# PIC32MX564F128H register map
Vendor: Microchip
Registers are 32-bit, read-write, reset 0x0 unless marked. A register's access mark holds for its fields unless they carry their own. Addresses are absolute, and some are shared; only a register's first bit layout is shown; [hi:lo] are bit positions; {n}, {i} and the like mark numbered series.

## UART2
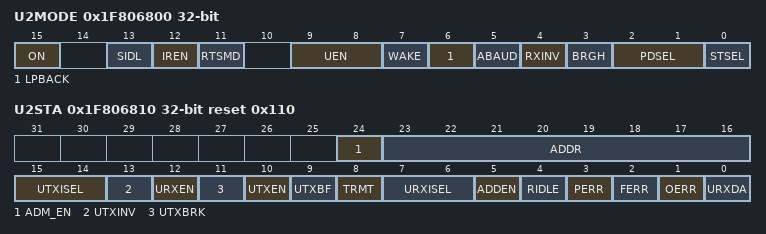
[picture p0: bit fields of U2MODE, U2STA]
0x1F806800 U2MODE
  [15] ON, [13] SIDL, [12] IREN, [11] RTSMD, [9:8] UEN, [7] WAKE, [6] LPBACK, [5] ABAUD, [4] RXINV, [3] BRGH, [2:1] PDSEL, [0] STSEL
0x1F806810 U2STA reset 0x110
  [24] ADM_EN
  [23:16] ADDR
  [15:14] UTXISEL
  [13] UTXINV
  [12] URXEN
  [11] UTXBRK
  [10] UTXEN
  [9] UTXBF ro
  [8] TRMT ro
  [7:6] URXISEL
  [5] ADDEN
  [4] RIDLE ro
  [3] PERR ro
  [2] FERR ro
  [1] OERR — (can only be cleared)
  [0] URXDA ro
0x1F806820 U2TXREG reset not defined — (power-on value -----------------------xxxxxxxxx)
  [8:0] U2TXREG
0x1F806830 U2RXREG ro
  [8:0] U2RXREG
0x1F806840 U2BRG
  [15:0] BRG

## UART5
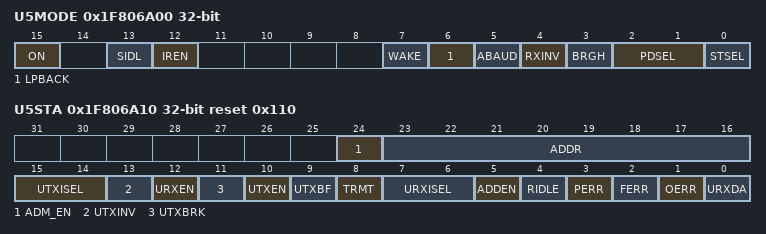
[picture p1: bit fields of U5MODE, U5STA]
0x1F806A00 U5MODE
  [15] ON, [13] SIDL, [12] IREN, [7] WAKE, [6] LPBACK, [5] ABAUD, [4] RXINV, [3] BRGH, [2:1] PDSEL, [0] STSEL
0x1F806A10 U5STA reset 0x110
  [24] ADM_EN
  [23:16] ADDR
  [15:14] UTXISEL
  [13] UTXINV
  [12] URXEN
  [11] UTXBRK
  [10] UTXEN
  [9] UTXBF ro
  [8] TRMT ro
  [7:6] URXISEL
  [5] ADDEN
  [4] RIDLE ro
  [3] PERR ro
  [2] FERR ro
  [1] OERR — (can only be cleared)
  [0] URXDA ro
0x1F806A20 U5TXREG reset not defined — (power-on value -----------------------xxxxxxxxx)
  [8:0] U5TXREG
0x1F806A30 U5RXREG ro
  [8:0] U5RXREG
0x1F806A40 U5BRG
  [15:0] BRG

## PMP
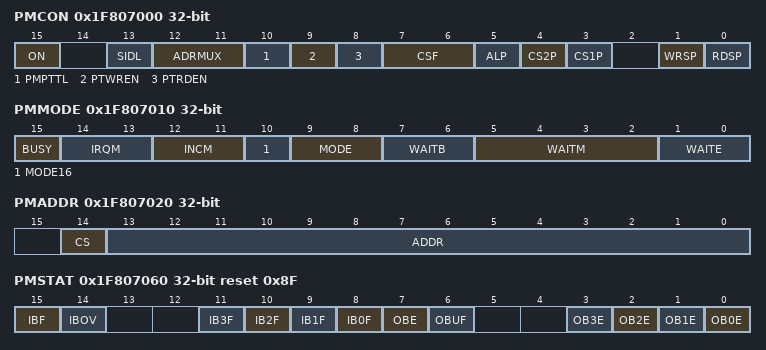
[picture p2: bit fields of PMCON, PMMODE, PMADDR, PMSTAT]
0x1F807000 PMCON
  [15] ON, [13] SIDL, [12:11] ADRMUX, [10] PMPTTL, [9] PTWREN, [8] PTRDEN, [7:6] CSF, [5] ALP, [4] CS2P, [3] CS1P, [1] WRSP, [0] RDSP
0x1F807010 PMMODE
  [15] BUSY ro, [14:13] IRQM, [12:11] INCM, [10] MODE16, [9:8] MODE, [7:6] WAITB, [5:2] WAITM, [1:0] WAITE
0x1F807020 PMADDR
  [14] CS, [13:0] ADDR
0x1F807030 PMDOUT
  [31:0] DATAOUT
0x1F807040 PMDIN
  [31:0] DATAIN
0x1F807050 PMAEN
  [15:0] PTEN
0x1F807060 PMSTAT reset 0x8F
  [15] IBF ro, [14] IBOV, [n+8] IB{n}F ro (n=0..3), [7] OBE ro, [6] OBUF, [n] OB{n}E ro (n=0..3)

## ADC10
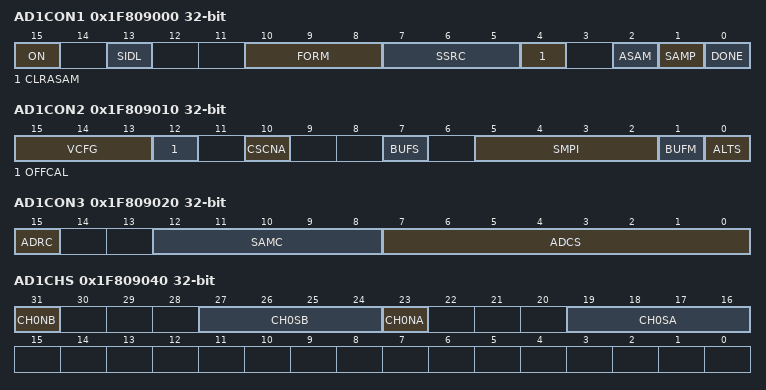
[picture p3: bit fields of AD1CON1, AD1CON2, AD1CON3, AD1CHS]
0x1F809000 AD1CON1
  [15] ON
  [13] SIDL
  [10:8] FORM
  [7:5] SSRC
  [4] CLRASAM
  [2] ASAM
  [1] SAMP
  [0] DONE — (can only be cleared)
0x1F809010 AD1CON2
  [15:13] VCFG, [12] OFFCAL, [10] CSCNA, [7] BUFS ro, [5:2] SMPI, [1] BUFM, [0] ALTS
0x1F809020 AD1CON3
  [15] ADRC, [12:8] SAMC, [7:0] ADCS
0x1F809040 AD1CHS
  [31] CH0NB, [27:24] CH0SB, [23] CH0NA, [19:16] CH0SA
0x1F809050 AD1CSSL
  [15:0] CSSL
0x1F809060 AD1PCFG
  [15:0] PCFG
{0x1F809070+0x10*i} ADC1BUF{i} ro (i=0..9)
0x1F809110 ADC1BUFA ro
0x1F809120 ADC1BUFB ro
0x1F809130 ADC1BUFC ro
0x1F809140 ADC1BUFD ro
0x1F809150 ADC1BUFE ro
0x1F809160 ADC1BUFF ro

## CVR
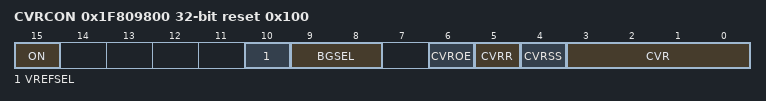
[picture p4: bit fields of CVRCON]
0x1F809800 CVRCON reset 0x100
  [15] ON, [10] VREFSEL, [9:8] BGSEL, [6] CVROE, [5] CVRR, [4] CVRSS, [3:0] CVR

## CMP1
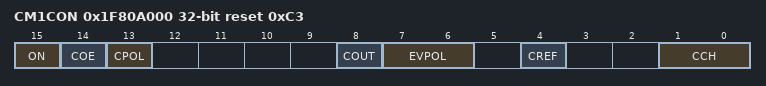
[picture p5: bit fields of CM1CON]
0x1F80A000 CM1CON reset 0xC3
  [15] ON, [14] COE, [13] CPOL, [8] COUT, [7:6] EVPOL, [4] CREF, [1:0] CCH

## CMP2
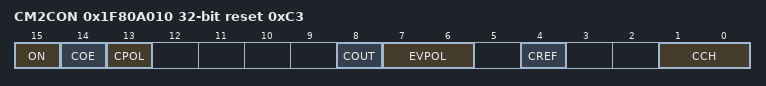
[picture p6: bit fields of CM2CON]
0x1F80A010 CM2CON reset 0xC3
  [15] ON, [14] COE, [13] CPOL, [8] COUT, [7:6] EVPOL, [4] CREF, [1:0] CCH

## cmp_control_pb
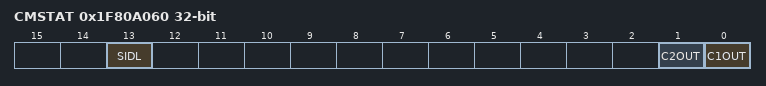
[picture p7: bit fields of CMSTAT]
0x1F80A060 CMSTAT
  [13] SIDL, [1] C2OUT ro, [0] C1OUT ro

## OSC
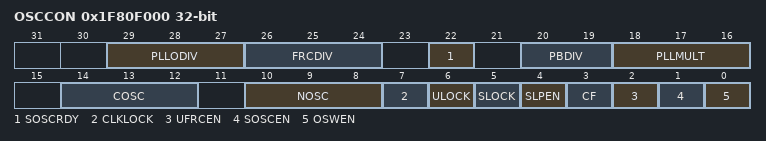
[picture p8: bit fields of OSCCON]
0x1F80F000 OSCCON reset not defined — (power-on value --qqq001-00qqqqq-000-qqq000000q0)
  [29:27] PLLODIV, [26:24] FRCDIV, [22] SOSCRDY, [20:19] PBDIV, [18:16] PLLMULT, [14:12] COSC, [10:8] NOSC, [7] CLKLOCK, [6] ULOCK, [5] SLOCK, [4] SLPEN, [3] CF, [2] UFRCEN, [1] SOSCEN, [0] OSWEN
0x1F80F010 OSCTUN
  [5:0] TUN

## CFG
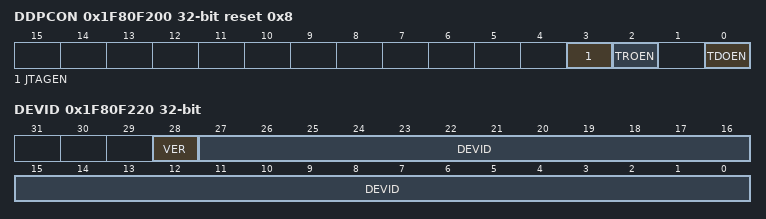
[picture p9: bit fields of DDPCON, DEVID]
0x1F80F200 DDPCON reset 0x8
  [3] JTAGEN, [2] TROEN, [0] TDOEN
0x1F80F220 DEVID ro reset not defined — (power-on value xxxxxxxxxxxxxxxxxxxxxxxxxxxxxxxx)
  [28] VER, [27:0] DEVID
0x1F80F230 SYSKEY ro reset not defined — (power-on value xxxxxxxxxxxxxxxxxxxxxxxxxxxxxxxx)
